AUTOSAR XML (schema 4-0-3)
standard types defined: uint8, Boolean, UInt16, UInt32, UInt8
package /AUTOSAR_Platform/DataConstrs
  range DC_Boolean: raw 0..1
  range DC_UInt16: raw 0..65535
  range DC_UInt8: raw 0..255
package /PATAC/Facility/DataTypes/Implementation
  compu method COMPU_Boolean: 0=FALSE, 1=TRUE
  unit NoUnit: factor-si-to-unit=1, offset-si-to-unit=0
package /PATAC/MSM/ComponentTypes
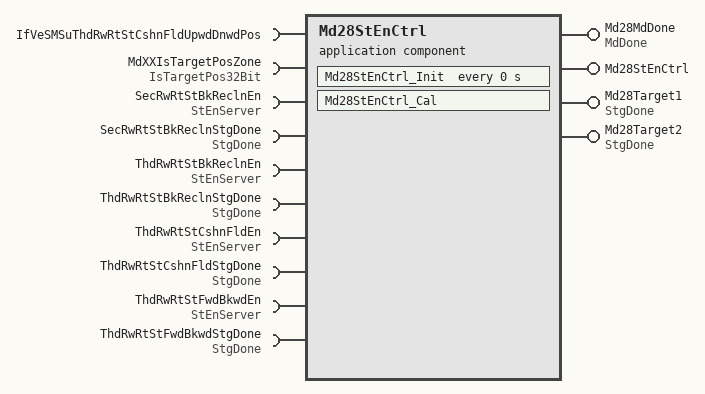
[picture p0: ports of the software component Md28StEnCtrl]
  application sw component type Md28StEnCtrl
    4 x provide port:
      Md28MdDone: nonqueued-sender-com-spec{data-element=MdDone/Val, init-value=0}, provided-interface=MdDone
      Md28StEnCtrl: server-com-spec{operation=Cal, queue-length=1}, provided-interface=Md28StEnCtrl
      Md28Target1: nonqueued-sender-com-spec{data-element=StgDone/Val, init-value=0}, provided-interface=StgDone
      Md28Target2: nonqueued-sender-com-spec{data-element=StgDone/Val, init-value=0}, provided-interface=StgDone
    10 x require port:
      IfVeSMSuThdRwRtStCshnFldUpwdDnwdPos: nonqueued-receiver-com-spec{data-element=IfVeSMSuThdRwRtStCshnFldUpwdDnwdPos/Val, filter=data-filter-type=ALWAYS, init-value=0}, required-interface=IfVeSMSuThdRwRtStCshnFldUpwdDnwdPos
      MdXXIsTargetPosZone: nonqueued-receiver-com-spec{data-element=IsTargetPos32Bit/Val, filter=data-filter-type=ALWAYS, init-value=0}, required-interface=IsTargetPos32Bit
      SecRwRtStBkReclnEn: required-com-specs=[Clear, Get, Set], required-interface=StEnServer
      SecRwRtStBkReclnStgDone: nonqueued-receiver-com-spec{data-element=StgDone/Val, filter=data-filter-type=ALWAYS, init-value=0}, required-interface=StgDone
      ThdRwRtStBkReclnEn: required-com-specs=[Clear, Get, Set], required-interface=StEnServer
      ThdRwRtStBkReclnStgDone: nonqueued-receiver-com-spec{data-element=StgDone/Val, filter=data-filter-type=ALWAYS, init-value=0}, required-interface=StgDone
      ThdRwRtStCshnFldEn: required-com-specs=[Clear, Get, Set], required-interface=StEnServer
      ThdRwRtStCshnFldStgDone: nonqueued-receiver-com-spec{data-element=StgDone/Val, filter=data-filter-type=ALWAYS, init-value=0}, required-interface=StgDone
      ThdRwRtStFwdBkwdEn: required-com-specs=[Clear, Get, Set], required-interface=StEnServer
      ThdRwRtStFwdBkwdStgDone: nonqueued-receiver-com-spec{data-element=StgDone/Val, filter=data-filter-type=ALWAYS, init-value=0}, required-interface=StgDone
    behavior Md28StEnCtrl_InternalBehavior
      operation invoked event OIT_Md28StEnCtrl_Cal_Md28StEnCtrl_Cal: start-on-event=Md28StEnCtrl_Cal, operation=Md28StEnCtrl.Cal
      timing event Md28StEnCtrl_InitEvent: start-on-event=Md28StEnCtrl_Init, period=0
      runnable Md28StEnCtrl_Cal
        data-receive-point-by-arguments:
          6 x access:
            REC_IfVeSMSuThdRwRtStCshnFldUpwdDnwdPos_Val: accessed-variable=IfVeSMSuThdRwRtStCshnFldUpwdDnwdPos.Val
            REC_MdXXIsTargetPosZone_Val: accessed-variable=MdXXIsTargetPosZone.Val
            REC_SecRwRtStBkReclnStgDone_Val: accessed-variable=SecRwRtStBkReclnStgDone.Val
            REC_ThdRwRtStBkReclnStgDone_Val: accessed-variable=ThdRwRtStBkReclnStgDone.Val
            REC_ThdRwRtStCshnFldStgDone_Val: accessed-variable=ThdRwRtStCshnFldStgDone.Val
            REC_ThdRwRtStFwdBkwdStgDone_Val: accessed-variable=ThdRwRtStFwdBkwdStgDone.Val
        data-send-points:
          access SEND_Md28MdDone_Val: accessed-variable=Md28MdDone.Val
          access SEND_Md28Target1_Val: accessed-variable=Md28Target1.Val
          access SEND_Md28Target2_Val: accessed-variable=Md28Target2.Val
        8 x sync call, all with timeout=0:
          SC_SecRwRtStBkReclnEn_Clear: operation=SecRwRtStBkReclnEn.Clear
          SC_SecRwRtStBkReclnEn_Set: operation=SecRwRtStBkReclnEn.Set
          SC_ThdRwRtStBkReclnEn_Clear: operation=ThdRwRtStBkReclnEn.Clear
          SC_ThdRwRtStBkReclnEn_Set: operation=ThdRwRtStBkReclnEn.Set
          SC_ThdRwRtStCshnFldEn_Clear: operation=ThdRwRtStCshnFldEn.Clear
          SC_ThdRwRtStCshnFldEn_Set: operation=ThdRwRtStCshnFldEn.Set
          SC_ThdRwRtStFwdBkwdEn_Clear: operation=ThdRwRtStFwdBkwdEn.Clear
          SC_ThdRwRtStFwdBkwdEn_Set: operation=ThdRwRtStFwdBkwdEn.Set
      runnable Md28StEnCtrl_Init
  swc implementation Md28StEnCtrl_Implementation: behavior=Md28StEnCtrl_InternalBehavior
    code-descriptors:
      code Default: artifact-descriptors=autosar-engineering-object={short-label=Default, category=SWSRC}
package /PATAC/MSM/ModeAdjust/Interfaces
  sender receiver interface IfVeSMSuThdRwRtStCshnFldUpwdDnwdPos: invalidation-policy{data-element=IfVeSMSuThdRwRtStCshnFldUpwdDnwdPos/Val, handle-invalid=DONT-INVALIDATE}
    data Val: type=UInt16
package /PATAC/MSM/ModeAdjust/PortInterface
  client server interface Md28StEnCtrl
    operation Cal
  client server interface StEnServer
    operation Clear
      arg data: type=UInt8, direction=IN, server-argument-impl-policy=USE-ARGUMENT-TYPE
    operation Get
      arg data: type=UInt32, direction=OUT, server-argument-impl-policy=USE-ARGUMENT-TYPE
    operation Set
      arg data: type=UInt8, direction=IN, server-argument-impl-policy=USE-ARGUMENT-TYPE
  sender receiver interface IsTargetPos32Bit: invalidation-policy{data-element=IsTargetPos32Bit/Val, handle-invalid=DONT-INVALIDATE}
    data Val: type=UInt32
  sender receiver interface MdDone: invalidation-policy{data-element=MdDone/Val, handle-invalid=DONT-INVALIDATE}
    data Val: type=UInt8
  sender receiver interface StgDone: invalidation-policy{data-element=StgDone/Val, handle-invalid=DONT-INVALIDATE}
    data Val: type=Boolean
